# R7FA4L1BD register map
Vendor: Renesas Electronics Corporation; Series: RA4; File version: 0.90.02
CPU: CM33 r0p4, little endian, MPU, FPU, VTOR, 4 interrupt priority bits, 96 interrupts
Registers are 32-bit, read-write, reset 0x0 unless marked. A register's access mark holds for its fields unless they carry their own. Offsets are from the block's base; [hi:lo] are bit positions.

## ECCMB
Base 0x4012F000
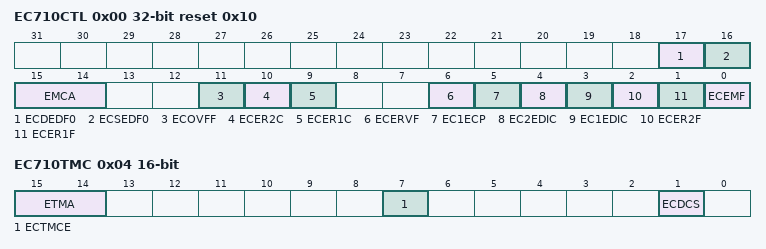
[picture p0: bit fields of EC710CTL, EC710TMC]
0x00 EC710CTL reset 0x10 — ECC Control Register
  [17] ECDEDF0 ro — 2-bit ECC Error Address Detection Flag
  [16] ECSEDF0 ro — 1-bit ECC Error Address Detection Flag
  [15:14] EMCA — ECC Error Detection Enable Access Control
  [11] ECOVFF ro — ECC Overflow Detection Flag
  [10] ECER2C — 2-bit ECC Error Detection Flag Clear
  [9] ECER1C — Accumulating ECC Error Detection and Correction Flag Clear
  [6] ECERVF — ECC Error Detection Enable
  [5] EC1ECP — 1-bit ECC Error Correction Permission
  [4] EC2EDIC — 2-bit ECC Error Detection Interrupt Control
  [3] EC1EDIC — 1-bit ECC Error Detection Interrupt Control
  [2] ECER2F ro — 2-bit ECC Error Detection Flag
  [1] ECER1F ro — 1-bit ECC Error Detection and Correction Flag
  [0] ECEMF ro — ECC Error Message Flag
0x04 EC710TMC 16-bit — ECC Test Mode Control Register
  [15:14] ETMA — ECC Test Mode Bit Access Control
  [7] ECTMCE — ECC Test Mode Control Enable
  [1] ECDCS — ECC Decode Input Select
0x0C EC710TED — ECC Test Substitute Data Register
  [31:0] ECEDB — ECC Test Substitute Data
0x10 EC710EAD0 ro — ECC Error Address Register
  [9:0] ECEAD — ECC Error Address

## GPT_OPS — Output Phase Switching Controller
Base 0x40169A00
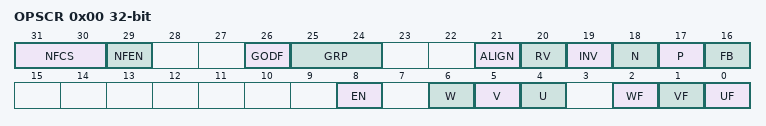
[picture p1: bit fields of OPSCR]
0x00 OPSCR — Output Phase Switching Control Register
  [31:30] NFCS — External Input Noise Filter Clock Selection
  [29] NFEN — External Input Noise Filter Enable
  [26] GODF — Group Output Disable Function
  [25:24] GRP — Output Disabled Source Selection
  [21] ALIGN — Input Phase Alignment
  [20] RV — Output Phase Rotation Direction Reversal Control
  [19] INV — Output Phase Invert Control
  [18] N — Negative,Phase Output (N) Control
  [17] P — Positive,Phase Output (P) Control
  [16] FB — External Feedback Signal Enable
  [8] EN — Output Phase Enable
  [6] W ro — Input W,Phase Monitor
  [5] V ro — Input V,Phase Monitor
  [4] U ro — Input U,Phase Monitor
  [2] WF
  [1] VF
  [0] UF

## DAC12 — 12-bit D/A converter
Base 0x40171000
0x00 DADR0 16-bit — D/A Data Register 0
0x04 DACR 8-bit reset 0x1F — D/A Control Register
  [6] DAOE0 — D/A Output Enable 0
0x05 DADPR 8-bit — DADR0 Format Select Register
  [7] DPSEL — DADR0 Format Select
0x06 DAADSCR 8-bit — D/A A/D Synchronous Start Control Register
  [7] DAADST — D/A A/D Synchronous Conversion
0x07 DAVREFCR 8-bit — D/A VREF Control Register
  [0] REF — D/A Reference Voltage Select

## FLCN — Flash I/O Registers
Base 0x407EC000
0x90 DFLCTL 8-bit — Data Flash Control Register
  [0] DFLEN — Data Flash Access Enable
0x228 TSCDR 16-bit ro reset not defined — Temperature Sensor Calibration Data Register
  [15:0] TSCDR — Temperature Sensor Calibration Data
0x3FC4 FLDWAITR 8-bit — Memory Wait Cycle Control Register for Data Flash
  [0] FLDWAIT1 — Memory Wait Cycle Select for Data Flash
0x3FC8 PFBER 8-bit — Prefetch Buffer Enable Register
  [0] PFBE — Prefetch Buffer Enable bit

## CIBC — Code Flash
Base 0x407EC200
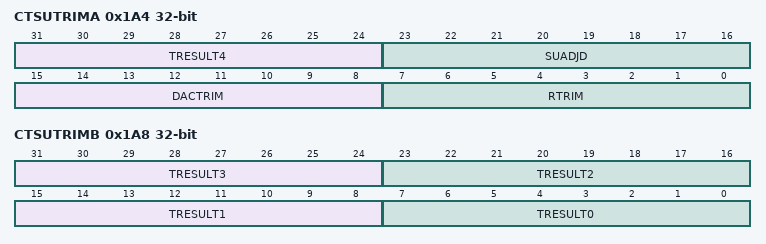
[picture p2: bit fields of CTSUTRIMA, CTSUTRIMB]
0x1A4 CTSUTRIMA reset not defined — CTSU Trimming Register A
  [31:24] TRESULT4 — Coefficient of variation for the reference load resistance
  [23:16] SUADJD — CTSU SUCLK Frequency Adjustment
  [15:8] DACTRIM — Linearity Adjustment of Offset Current
  [7:0] RTRIM — CTSU Reference Resistance Adjustment
0x1A8 CTSUTRIMB reset not defined — CTSU Trimming Register B
  [31:24] TRESULT3 — The coefficient of variation for the 60 kΩ reference load resistance is stored.
  [23:16] TRESULT2 — The coefficient of variation for the 30 kΩ reference load resistance is stored.
  [15:8] TRESULT1 — The coefficient of variation for the 15 kΩ reference load resistance is stored.
  [7:0] TRESULT0 — The coefficient of variation for the 7.5 kΩ reference load resistance is stored.
